AUTOSAR XML (schema 4.0)
package /ADAS_Components
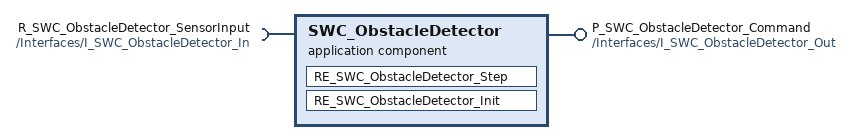
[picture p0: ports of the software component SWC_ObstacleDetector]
  application sw component type SWC_ObstacleDetector  # AUTOSAR Application SWC SWC_ObstacleDetector for ADAS control sub-system
    provide port P_SWC_ObstacleDetector_Command: provided-interface=/Interfaces/I_SWC_ObstacleDetector_Out
    require port R_SWC_ObstacleDetector_SensorInput: required-interface=/Interfaces/I_SWC_ObstacleDetector_In
    behavior SWC_ObstacleDetector_Behavior
      runnable RE_SWC_ObstacleDetector_Step: symbol=SWC_ObstacleDetector_Step
      runnable RE_SWC_ObstacleDetector_Init: symbol=SWC_ObstacleDetector_Init
  sender receiver interface I_SWC_ObstacleDetector_Out  # Sender Receiver Interface for SWC_ObstacleDetector outputs
    data DE_SWC_ObstacleDetector_Signal: type=/AUTOSAR/Platform/uint32
  sender receiver interface I_SWC_ObstacleDetector_In  # Sender Receiver Interface for SWC_ObstacleDetector inputs
    data DE_SWC_ObstacleDetector_RawData: type=/AUTOSAR/Platform/uint16
